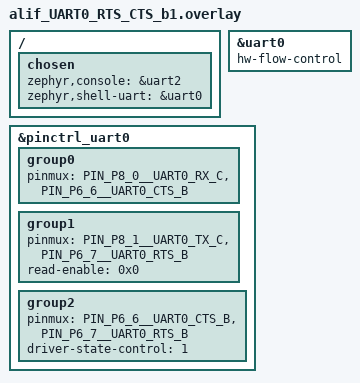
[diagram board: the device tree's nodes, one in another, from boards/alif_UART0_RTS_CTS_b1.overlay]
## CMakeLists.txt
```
cmake_minimum_required(VERSION 3.20.0)
find_package(Zephyr REQUIRED HINTS $ENV{ZEPHYR_BASE})

project(uart_tests)

target_sources(app PRIVATE
    src/main.c
)

# RTS/CTS lives in uart_internal_loopback.c (guarded by CONFIG_TEST_UART_RTSCTS).
# Compile that file when either the internal-loopback or the RTS/CTS suite
# is enabled so uart_RTSCTS_suite is not registered with zero tests.
if(CONFIG_TEST_INTERNAL_LB OR CONFIG_TEST_UART_RTSCTS)
  target_sources(app PRIVATE src/uart_internal_loopback.c)
endif()

target_sources_ifdef(CONFIG_TEST_EXTERNAL_LB app PRIVATE src/uart_external_loopback.c)

target_sources_ifdef(CONFIG_TEST_UART_DMA app PRIVATE src/uart_dma_tests.c)

target_sources_ifdef(CONFIG_TEST_STRESS app PRIVATE src/uart_stress.c)

target_sources_ifdef(CONFIG_TEST_PERFORMANCE app PRIVATE src/uart_perf.c)

target_sources_ifdef(CONFIG_TEST_UART_LINE_ERRORS app PRIVATE src/uart_line_errors.c)

if(CONFIG_TEST_INTERNAL_LB OR CONFIG_TEST_EXTERNAL_LB OR CONFIG_TEST_UART_FIFO)
  target_sources(app PRIVATE src/uart_fifo_depth.c)
endif()

target_sources_ifdef(CONFIG_TEST_UART_HOTPLUG app PRIVATE src/uart_hotplug.c)
```

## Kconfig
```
mainmenu "UART Test Suite Configuration"

source "Kconfig.zephyr"

config TEST_INTERNAL_LB
	bool "Enable UART internal loopback test suite"
	help
	  Build src/uart_internal_loopback.c and register
	  uart_internal_loopback.

config TEST_EXTERNAL_LB
	bool "Enable UART external loopback test suite"
	help
	  Build src/uart_external_loopback.c. Requires a physical TX-RX
	  connection between zephyr,devnode1 and zephyr,devnode2.

config TEST_UART_RTSCTS
	bool "Enable UART RTS/CTS flow control test suite"
	help
	  Builds src/uart_internal_loopback.c (same source as
	  TEST_INTERNAL_LB) so test_interrupt_internal_loopback_flowctrl_rts_cts
	  is compiled, and registers uart_RTSCTS_suite. Apply snippet
	  uart0-rts-cts (and boards/alif_uart.overlay) so hw-flow-control
	  is present on zephyr,devnode1.

config TEST_UART_DMA
	bool "Enable UART DMA async API test suite"
	help
	  Build src/uart_dma_tests.c. Also enable the DMA / async-API
	  options in dma.conf (EXTRA_CONF_FILE=dma.conf) and apply
	  snippet alif-uart-dma so zephyr,devnode1 is DMA-wired
	  (per-board overlay selected by the snippet).

config TEST_STRESS
	bool "Enable UART TX stress test suite"
	help
	  Build src/uart_stress.c and register uart_stress. Sends large
	  interrupt-driven TX bursts on zephyr,devnode1 (300 KiB and
	  1 250 000 bytes). Uses the overlay current-speed as baud rate.

config TEST_PERFORMANCE
	bool "Enable UART external-loopback performance test suite"
	help
	  Build src/uart_perf.c and register uart_performance. Requires
	  a physical TX-RX connection between zephyr,devnode1 and
	  zephyr,devnode2. Measures timed 1 KiB and 25 KiB transfers at
	  115200, 921600, 2500000, and 5000000 baud. Unsupported rates
	  are skipped at runtime.

config TEST_UART_LINE_ERRORS
	bool "Enable UART line-break and false-start-bit tests"
	select UART_LINE_CTRL
	select UART_NS16550_LINE_CTRL
	help
	  Build src/uart_line_errors.c. Needs TX-RX wire between
	  zephyr,devnode1 and zephyr,devnode2.

	  UART_LINE_CTRL enables the public uart_line_ctrl_set() API.
	  UART_NS16550_LINE_CTRL hooks the ns16550 driver (LCR break).
	  Without the second option uart_line_ctrl_set(BRK) returns
	  -ENOSYS and the suite skips.

config TEST_UART_FIFO
	  bool "Enable UART FIFO 32/33rd-byte boundary suite"
	  help
		Build src/uart_fifo_depth.c and register uart_fifo. TX 33rd
		byte is also built with TEST_INTERNAL_LB. RX 33rd byte needs
		a physical TX-RX wire (enable this flag or TEST_EXTERNAL_LB).

config TEST_UART_HOTPLUG
	bool "Enable UART hard-plug / unplug suite"
	help
		Build src/uart_hotplug.c and register uart_hotplug. Needs a
		TX-RX wire. Unmounts TX mid-transfer, checks RX stall latency
		and lost bytes, then remounts and recovers.
```

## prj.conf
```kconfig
CONFIG_SERIAL=y
CONFIG_UART_INTERRUPT_DRIVEN=y
CONFIG_ZTEST=y
CONFIG_EVENTS=y
CONFIG_LOG=y

CONFIG_MAIN_STACK_SIZE=2048
CONFIG_SYSTEM_WORKQUEUE_STACK_SIZE=2048

CONFIG_TEST_INTERNAL_LB=y
```

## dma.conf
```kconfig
# DMA-specific configuration for the UART DMA async-API test suite.
#
# Kept separate from prj.conf so that the DMA / async-API options do not
# affect the non-DMA UART test suites. Disables the interrupt-driven
# internal-loopback suite so it does not share zephyr,devnode1 with the
# DMA suite.

CONFIG_UART_ASYNC_API=y
CONFIG_DMA=y
CONFIG_DMA_PL330=y
CONFIG_TEST_UART_DMA=y
CONFIG_TEST_INTERNAL_LB=n
```

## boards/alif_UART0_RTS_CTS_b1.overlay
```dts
/* Copyright (C) 2025 Alif Semiconductor - All Rights Reserved.
 * Use, distribution and modification of this code is permitted under the
 * terms stated in the Alif Semiconductor Software License Agreement
 *
 * You should have received a copy of the Alif Semiconductor Software
 * License Agreement with this file. If not, please write to:
 * contact@alifsemi.com, or visit: https://alifsemi.com/license
 */

/* Enable H/W flow control(RTS-CTS) for UART0 */
/ {
	chosen {
		zephyr,console = &uart2;
		zephyr,shell-uart = &uart0;
	};
};

&uart0 {
	hw-flow-control;
	status = "okay";
};

&pinctrl_uart0 {
	group0 {
		pinmux = <PIN_P8_0__UART0_RX_C>,
			 <PIN_P6_6__UART0_CTS_B>;
	};
	group1 {
		pinmux = <PIN_P8_1__UART0_TX_C>,
			 <PIN_P6_7__UART0_RTS_B>;
		read-enable = <0x0>;
	};
	group2 {
		pinmux = <PIN_P6_6__UART0_CTS_B>,
			 <PIN_P6_7__UART0_RTS_B>;
		driver-state-control = <1>;
	};
};
```

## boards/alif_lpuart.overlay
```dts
/ {
	chosen {
		zephyr,devnode1 = &lpuart;
		zephyr,devnode2 = &uart1;
	};
};

&lpuart {
	status = "okay";
};

&uart1 {
	status = "okay";
};
```

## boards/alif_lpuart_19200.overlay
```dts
/ {
	chosen {
		zephyr,devnode1 = &lpuart;
		zephyr,devnode2 = &uart5;
	};
};

&lpuart {
	current-speed = <19200>;
	status = "okay";
};

&uart5 {
	current-speed = <19200>;
	status = "okay";
};
```

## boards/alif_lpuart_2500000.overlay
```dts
/ {
	chosen {
		zephyr,devnode1 = &lpuart;
		zephyr,devnode2 = &uart5;
	};
};

&lpuart {
	current-speed = <2500000>;
	status = "okay";
};

&uart5 {
	current-speed = <2500000>;
	status = "okay";
};
```

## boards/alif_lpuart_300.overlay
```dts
/ {
	chosen {
		zephyr,devnode1 = &lpuart;
		zephyr,devnode2 = &uart5;
	};
};

&lpuart {
	current-speed = <300>;
	status = "okay";
};

&uart5 {
	current-speed = <300>;
	status = "okay";
};
```

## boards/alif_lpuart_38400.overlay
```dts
/ {
	chosen {
		zephyr,devnode1 = &lpuart;
		zephyr,devnode2 = &uart5;
	};
};

&lpuart {
	current-speed = <38400>;
	status = "okay";
};

&uart5 {
	current-speed = <38400>;
	status = "okay";
};
```

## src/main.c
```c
/* Copyright (C) Alif Semiconductor - All Rights Reserved.
 * Use, distribution and modification of this code is permitted under the
 * terms stated in the Alif Semiconductor Software License Agreement
 *
 * You should have received a copy of the Alif Semiconductor Software
 * License Agreement with this file. If not, please write to:
 * contact@alifsemi.com, or visit: https://alifsemi.com/license
 */

/**
 * @file
 * @brief UART test shared state, utility helpers, and test-suite registration.
 *
 * This file owns the global UART configuration structs and ISR-shared
 * variables consumed by the loopback, stress, and performance modules.
 * It also provides small helper functions
 * (baud-rate look-up, config-result checking, IRQ-callback validation)
 * and the ZTEST_SUITE() declarations gated by Kconfig flags.
 */

#include "test_uart.h"

/*
 * ---------------------------------------------------------------------------
 *  UART configuration structs — one per logical role.
 *  All default to 115200 / 8N1 / no flow-control.
 * ---------------------------------------------------------------------------
 */
struct uart_config uart_cfg = {
	.baudrate  = 115200,
	.parity    = UART_CFG_PARITY_NONE,
	.stop_bits = UART_CFG_STOP_BITS_1,
	.data_bits = UART_CFG_DATA_BITS_8,
	.flow_ctrl = UART_CFG_FLOW_CTRL_NONE,
};

struct uart_config uart_cfg_rx = {
	.baudrate  = 115200,
	.parity    = UART_CFG_PARITY_NONE,
	.stop_bits = UART_CFG_STOP_BITS_1,
	.data_bits = UART_CFG_DATA_BITS_8,
	.flow_ctrl = UART_CFG_FLOW_CTRL_NONE,
};

struct uart_config uart_cfg_tx = {
	.baudrate  = 115200,
	.parity    = UART_CFG_PARITY_NONE,
	.stop_bits = UART_CFG_STOP_BITS_1,
	.data_bits = UART_CFG_DATA_BITS_8,
	.flow_ctrl = UART_CFG_FLOW_CTRL_NONE,
};

/*
 * ---------------------------------------------------------------------------
 *  ISR-shared state: internal loopback ("auto") path
 * ---------------------------------------------------------------------------
 */
volatile bool data_transmitted_auto;
volatile bool data_received_auto;
volatile int tx_data_idx1;
volatile int rec_count_auto;
volatile int char_sent1;
uint8_t rx_verify_buf_auto[DATASIZE];

/*
 * ---------------------------------------------------------------------------
 *  ISR-shared state: external loopback path
 * ---------------------------------------------------------------------------
 */
volatile bool data_transmitted;
volatile bool data_received;
volatile int tx_data_idx;
volatile int char_sent;
volatile int rec_bytes;

/*
 * ---------------------------------------------------------------------------
 *  Utility helpers
 * ---------------------------------------------------------------------------
 */

/**
 * @brief Set the baud rate of a UART device at runtime.
 *
 * Reads the current configuration via uart_config_get(), updates only
 * the baud-rate field, then applies it with uart_configure().  This
 * lets a single compiled binary test every supported rate without
 * per-baud overlay recompilation.
 *
 * @param uart_dev       UART device to reconfigure.
 * @param test_baudrate  Desired baud rate in bps.
 * @return 0 on success, negative errno on failure.
 */
int set_baudrate(const struct device *uart_dev, uint32_t test_baudrate)
{
	struct uart_config current_cfg;
	int err;

	err = uart_config_get(uart_dev, &current_cfg);
	if (err != 0) {
		TC_PRINT("uart_config_get failed (ret=%d)\n", err);
		return err;
	}

	current_cfg.baudrate = test_baudrate;
	err = uart_configure(uart_dev, &current_cfg);
	if (err != 0) {
		TC_PRINT("uart_configure failed for baudrate %u (ret=%d)\n",
			 test_baudrate, err);
	}

	return err;
}

int check_baud(int num)
{
	switch (num) {
	case UART_BAUD_300:
		return 300;
	case UART_BAUD_9600:
		return 9600;
	case UART_BAUD_19200:
		return 19200;
	case UART_BAUD_38400:
		return 38400;
	case UART_BAUD_57600:
		return 57600;
	case UART_BAUD_115200:
		return 115200;
	case UART_BAUD_921600:
		return 921600;
	case UART_BAUD_2500000:
		return 2500000;
	default:
		TC_PRINT("INVALID BAUDRATE\t");
		return TC_SKIP;
	}
}

int check_stop_bits(int num)
{
	switch (num) {
	case UART_CFG_STOP_BITS_0_5:
		TC_PRINT("\nUART_CFG_STOP_BITS_0_5\n");
		return UART_CFG_STOP_BITS_0_5;
	case UART_CFG_STOP_BITS_1:
		TC_PRINT("\nUART_CFG_STOP_BITS_1\n");
		return UART_CFG_STOP_BITS_1;
	case UART_CFG_STOP_BITS_1_5:
		TC_PRINT("\nUART_CFG_STOP_BITS_1_5\n");
		return UART_CFG_STOP_BITS_1_5;
	case UART_CFG_STOP_BITS_2:
		TC_PRINT("\nUART_CFG_STOP_BITS_2\n");
		return UART_CFG_STOP_BITS_2;
	default:
		TC_PRINT("\nINVALID STOP BITS\n");
		return TC_SKIP;
	}
}

/**
 * @brief Map a parity index to its Zephyr UART_CFG_PARITY_* constant.
 *
 * @param num  Parity selector (0 = none … 4 = space).
 * @return The corresponding UART_CFG_PARITY_* value, or TC_SKIP.
 */
int check_parity_bits(int num)
{
	switch (num) {
	case UART_CFG_PARITY_NONE:
		TC_PRINT("\nUART_CFG_PARITY_NONE\n");
		return UART_CFG_PARITY_NONE;
	case UART_CFG_PARITY_ODD:
		TC_PRINT("\nUART_CFG_PARITY_ODD\n");
		return UART_CFG_PARITY_ODD;
	case UART_CFG_PARITY_EVEN:
		TC_PRINT("\nUART_CFG_PARITY_EVEN\n");
		return UART_CFG_PARITY_EVEN;
	case UART_CFG_PARITY_MARK:
		TC_PRINT("\nUART_CFG_PARITY_MARK\n");
		return UART_CFG_PARITY_MARK;
	case UART_CFG_PARITY_SPACE:
		TC_PRINT("\nUART_CFG_PARITY_SPACE\n");
		return UART_CFG_PARITY_SPACE;
	default:
		TC_PRINT("\nINVALID PARITY\n");
		return TC_SKIP;
	}
}

/**
 * @brief Non-fatal check of uart_configure() return value.
 *
 * Prints a diagnostic and returns -1 on any error so that the caller
 * can skip the current baud-rate / config iteration without aborting
 * the entire test.
 *
 * @param ret  Return value from uart_configure().
 * @return 0 on success, -1 on failure.
 */
int check_configure_result_loopback(int ret)
{
	switch (ret) {
	case -ENOSYS:
		TC_PRINT("Configuration not supported by device or driver\n");
		return -1;
	case -ENOTSUP:
		TC_PRINT("API is not enabled\n");
		return -1;
	default:
		if (ret < 0) {
			TC_PRINT("Negative errno %d\n", ret);
			return -1;
		} else if (ret != 0) {
			TC_PRINT("Configuration failed\n");
			return -1;
		}
		TC_PRINT("Configuration passed\n");
		return 0;
	}
}

/**
 * @brief Fatal check of uart_configure() return value.
 *
 * Calls zassert_equal(); the test is aborted if @p ret != 0.
 *
 * @param ret  Return value from uart_configure().
 * @return 0 (only reached on success).
 */
int check_configure_result(int ret)
{
	zassert_equal(ret, 0, "UART configuration failed (ret=%d)", ret);
	return 0;
}

int uart_irq_cb(int ret)
{
	switch (ret) {
	case 0:
		return 0;
	case -ENOSYS:
		TC_PRINT("Function is not supported\n");
		return -1;
	case -ENOTSUP:
		TC_PRINT("API is not enabled\n");
		return -1;
	default:
		if (ret < 0) {
			TC_PRINT("Negative errno %d from uart_irq_callback_user_data_set\n", ret);
			return -1;
		} else if (ret != 0) {
			TC_PRINT("Unexpected non-zero return value %d from "
			 "uart_irq_callback_user_data_set\n", ret);
			return -1;
		}
	}

	return 0;
}

/*
 * ---------------------------------------------------------------------------
 *  Test-suite registration (gated by Kconfig)
 * ---------------------------------------------------------------------------
 */

#if CONFIG_TEST_EXTERNAL_LB
/** External-loopback suite — requires a physical TX→RX wire between devnode1
 *  and devnode2.  Enabled with CONFIG_TEST_EXTERNAL_LB=y.
 */
ZTEST_SUITE(uart_external_loopback, NULL, NULL, NULL, NULL, NULL);
#endif

#if CONFIG_TEST_INTERNAL_LB
/** Internal-loopback suite — uses the UART's built-in loopback mode on
 *  devnode1.  Enabled with CONFIG_TEST_INTERNAL_LB=y.
 */
ZTEST_SUITE(uart_internal_loopback, NULL, NULL, NULL, NULL, NULL);
#endif

#if CONFIG_TEST_UART_RTSCTS
/** RTS/CTS flow control suite — tests hardware flow control on
 *  devnode1.  Enabled with CONFIG_TEST_UART_RTSCTS=y.
 */
ZTEST_SUITE(uart_RTSCTS_suite, NULL, NULL, NULL, NULL, NULL);
#endif

#if CONFIG_TEST_STRESS
/** TX stress suite — large interrupt-driven bursts on devnode1.
 *  Enabled with CONFIG_TEST_STRESS=y.
 */
ZTEST_SUITE(uart_stress, NULL, NULL, NULL, NULL, NULL);
#endif

#if CONFIG_TEST_PERFORMANCE
/** External-loopback performance suite — timed transfers between
 *  devnode1 and devnode2.  Enabled with CONFIG_TEST_PERFORMANCE=y.
 */
ZTEST_SUITE(uart_performance, NULL, NULL, NULL, NULL, NULL);
#endif
#if CONFIG_TEST_UART_LINE_ERRORS
ZTEST_SUITE(uart_line_errors, NULL, NULL, NULL, NULL, NULL);
#endif

#if CONFIG_TEST_INTERNAL_LB || CONFIG_TEST_EXTERNAL_LB || CONFIG_TEST_UART_FIFO
/** FIFO depth / 33rd-byte boundary (TX always; RX needs a wire). */
ZTEST_SUITE(uart_fifo, NULL, NULL, NULL, NULL, NULL);
#endif

/*
 * uart_hotplug is registered in uart_hotplug.c so its after-hook can
 * resume a suspended TX UART even when an assertion fails.
 * uart_dma is registered in uart_dma_tests.c for the same reason:
 * its before/after hooks own DMA buffer setup and release.
 */
```

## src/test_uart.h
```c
/* Copyright (C) Alif Semiconductor - All Rights Reserved.
 * Use, distribution and modification of this code is permitted under the
 * terms stated in the Alif Semiconductor Software License Agreement
 *
 * You should have received a copy of the Alif Semiconductor Software
 * License Agreement with this file. If not, please write to:
 * contact@alifsemi.com, or visit: https://alifsemi.com/license
 */
/**
 * @file
 * @brief UART test cases header file
 *
 * Common declarations for UART test suite covering internal/external
 * loopback, RTS/CTS, stress, and performance tests on Alif platforms.
 */

#ifndef TEST_UART_H_
#define TEST_UART_H_

#include <zephyr/drivers/uart.h>
#include <zephyr/ztest.h>
#include <zephyr/sys/util.h>

#if !DT_HAS_CHOSEN(zephyr_devnode1)
#error "Need DT chosen zephyr,devnode1 (alif_uart or alif_lpuart overlay)"
#endif

#if !DT_HAS_CHOSEN(zephyr_devnode2) && \
	(CONFIG_TEST_EXTERNAL_LB || CONFIG_TEST_PERFORMANCE || \
	 CONFIG_TEST_UART_LINE_ERRORS || CONFIG_TEST_UART_HOTPLUG)
#error "Need DT chosen zephyr,devnode2 (apply boards/alif_uart.overlay)"
#endif

/** Maximum receive-buffer size shared across test modules. */
#define DATASIZE        128

/** Hardware FIFO depth (bytes) for a single uart_fifo_fill / uart_fifo_read. */
#define FIFO_DEPTH      32

/** k_event bit signalling TX completion inside an ISR callback. */
#define TX_DONE_EVENT   BIT(0)

/** k_event bit signalling RX completion inside an ISR callback. */
#define RX_DONE_EVENT   BIT(1)

/** Floor value (ms) returned by uart_test_timeout_ms() for fast baud rates. */
#define UART_TEST_TIMEOUT_MS  3000

/**
 * @brief Compute a safe per-transfer timeout in milliseconds.
 *
 * Uses 8N1 framing (10 bits per byte) to estimate the raw transfer time,
 * then applies a 3x multiplier plus a 2 s margin.  Never returns less than
 * @ref UART_TEST_TIMEOUT_MS so that high-baud-rate transfers still get a
 * reasonable deadline.
 *
 * @param baudrate  Configured baud rate (bps).
 * @param size      Number of bytes to transfer.
 * @return Timeout in milliseconds.
 */
static inline int64_t uart_test_timeout_ms(uint32_t baudrate, int size)
{
	int64_t transfer_ms = ((int64_t)size * 10 * 1000) / baudrate;
	int64_t timeout = transfer_ms * 3 + 2000; /* 3x transfer time + 2s margin */

	return (timeout > UART_TEST_TIMEOUT_MS) ? timeout : UART_TEST_TIMEOUT_MS;
}

/*
 * Context structure passed as user_data to ISR callbacks.
 * Avoids calling strlen() in ISR context and supports binary data.
 */
struct uart_cb_ctx {
	const uint8_t *buf;  /* TX data buffer */
	int size;            /* TX data length (no NUL dependency) */
};

typedef enum {
	UART_BAUD_300,
	UART_BAUD_9600,
	UART_BAUD_19200,
	UART_BAUD_38400,
	UART_BAUD_57600,
	UART_BAUD_115200,
	UART_BAUD_921600,
	UART_BAUD_2500000,
} uart_config_baudrates;

/* Automation (internal loopback) state */
extern volatile bool data_transmitted_auto;
extern volatile bool data_received_auto;
extern volatile int tx_data_idx1;
extern volatile int rec_count_auto;
extern volatile int char_sent1;
extern uint8_t rx_verify_buf_auto[];

/* Manual (external loopback / stress) state */
extern volatile bool data_transmitted;
extern volatile bool data_received;
extern volatile int tx_data_idx;
extern volatile int char_sent;
extern volatile int rec_bytes;

extern struct uart_config uart_cfg;
extern struct uart_config uart_cfg_rx;
extern struct uart_config uart_cfg_tx;

/* Utility functions (main.c) */
extern int set_baudrate(const struct device *uart_dev, uint32_t test_baudrate);
extern int check_baud(int num);
extern int check_stop_bits(int num);
extern int check_parity_bits(int num);
extern int check_configure_result(int ret);
extern int check_configure_result_loopback(int ret);
extern int uart_irq_cb(int ret);

/* Helper macro to get current-speed from devicetree */
#define UART_GET_BAUDRATE(node) DT_PROP_OR(node, current_speed, 115200)

static inline uint32_t get_uart_baudrate_from_dt(void)
{
	return UART_GET_BAUDRATE(DT_CHOSEN(zephyr_devnode1));
}

#endif /* TEST_UART_H_ */
```

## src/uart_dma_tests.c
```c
/* Copyright (C) Alif Semiconductor - All Rights Reserved.
 * Use, distribution and modification of this code is permitted under the
 * terms stated in the Alif Semiconductor Software License Agreement
 *
 * You should have received a copy of the Alif Semiconductor Software
 * License Agreement with this file. If not, please write to:
 * contact@alifsemi.com, or visit: https://alifsemi.com/license
 */

#include <string.h>
#include "test_uart.h"

#if CONFIG_TEST_UART_DMA

#define RX_BUF_SIZE        64
#define TX_BUF_SIZE        64
#define TX_ABORT_BUF_SIZE  128

/*
 * RX may be fragmented across multiple UART_RX_RDY events. Each fragment
 * is pushed onto a message queue so that events arriving before the test
 * thread consumes them are preserved. A single semaphore would coalesce
 * (max-count) the events and the shared globals would be overwritten,
 * dropping earlier fragments.
 */
#define RX_MSGQ_DEPTH      16

struct rx_chunk {
	uint8_t *buf;
	size_t   offset;
	size_t   len;
};

static uint8_t rx_dma_buf_a[RX_BUF_SIZE];
static uint8_t rx_dma_buf_b[RX_BUF_SIZE];
static uint8_t tx_dma_buf[TX_BUF_SIZE];
static uint8_t tx_abort_buf[TX_ABORT_BUF_SIZE];

K_MSGQ_DEFINE(rx_msgq, sizeof(struct rx_chunk), RX_MSGQ_DEPTH, 4);

static struct k_sem tx_done_sem;
static struct k_sem rx_disabled_sem;
static struct k_sem buf_req_sem;
static struct k_sem buf_released_sem;

static volatile int last_tx_evt;

/* DMA-capable UART device under test (devnode1), resolved in the before hook. */
static const struct device *dma_uart_dev;

static void uart_dma_cb(const struct device *dev, struct uart_event *evt,
			void *user_data)
{
	ARG_UNUSED(dev);
	ARG_UNUSED(user_data);

	switch (evt->type) {
	case UART_RX_RDY: {
		struct rx_chunk chunk = {
			.buf    = evt->data.rx.buf,
			.offset = evt->data.rx.offset,
			.len    = evt->data.rx.len,
		};

		if (k_msgq_put(&rx_msgq, &chunk, K_NO_WAIT) != 0) {
			TC_PRINT("RX msgq overflow: dropping UART_RX_RDY fragment\n");
		}
		break;
	}
	case UART_TX_DONE:
		last_tx_evt = evt->type;
		TC_PRINT("UART_TX_DONE\n");
		k_sem_give(&tx_done_sem);
		break;
	case UART_TX_ABORTED:
		last_tx_evt = evt->type;
		TC_PRINT("UART_TX_ABORTED\n");
		k_sem_give(&tx_done_sem);
		break;
	case UART_RX_BUF_REQUEST:
		TC_PRINT("UART_RX_BUF_REQUEST\n");
		k_sem_give(&buf_req_sem);
		break;
	case UART_RX_BUF_RELEASED:
		TC_PRINT("UART_RX_BUF_RELEASED\n");
		k_sem_give(&buf_released_sem);
		break;
	case UART_RX_DISABLED:
		TC_PRINT("UART_RX_DISABLED\n");
		k_sem_give(&rx_disabled_sem);
		break;
	default:
		break;
	}
}

static int dma_uart_send(const struct device *dev, const uint8_t *data,
			 size_t len)
{
	int ret;

	ret = uart_tx(dev, data, len, SYS_FOREVER_US);
	if (ret < 0) {
		return ret;
	}

	ret = k_sem_take(&tx_done_sem, K_SECONDS(5));
	return ret;
}

/*
 * Per-test setup, invoked by the ztest framework before every test in
 * the uart_dma suite. Validates device readiness, resets all
 * synchronization primitives and buffers, and (re)installs the async
 * callback so each test starts from a clean, known state.
 */
static void uart_dma_before(void *fixture)
{
	ARG_UNUSED(fixture);
	int ret;

	dma_uart_dev = DEVICE_DT_GET(DT_CHOSEN(zephyr_devnode1));
	zassert_true(device_is_ready(dma_uart_dev),
		     "%s UART device not ready", dma_uart_dev->name);
	TC_PRINT("%s UART device is ready\n", dma_uart_dev->name);

	k_sem_init(&tx_done_sem, 0, 1);
	k_sem_init(&rx_disabled_sem, 0, 1);
	k_sem_init(&buf_req_sem, 0, 1);
	k_sem_init(&buf_released_sem, 0, 1);
	k_msgq_purge(&rx_msgq);

	last_tx_evt = -1;

	memset(rx_dma_buf_a, 0, RX_BUF_SIZE);
	memset(rx_dma_buf_b, 0, RX_BUF_SIZE);
	memset(tx_dma_buf, 0, TX_BUF_SIZE);

	ret = uart_callback_set(dma_uart_dev, uart_dma_cb, NULL);
	zassert_equal(ret, 0, "uart_callback_set failed (ret=%d)", ret);
}

/*
 * Per-test teardown: abort any in-flight TX and disable RX so the DMA
 * buffers are released and re-acquired cleanly between test cases,
 * regardless of whether the test passed or failed.
 */
static void uart_dma_after(void *fixture)
{
	ARG_UNUSED(fixture);

	if (dma_uart_dev == NULL) {
		return;
	}

	(void)uart_tx_abort(dma_uart_dev);
	if (uart_rx_disable(dma_uart_dev) == 0) {
		(void)k_sem_take(&rx_disabled_sem, K_SECONDS(1));
	}
}

/**
 * @brief Basic DMA TX/RX loopback test.
 *
 * Transmits a short string via DMA and verifies the identical
 * payload is received back via DMA RX.
 */
ZTEST(uart_dma, test_dma_basic_tx_rx)
{
	int ret;
	uint8_t tx_payload[] = "DMA loopback test!";
	size_t tx_len = strlen((char *)tx_payload);

	ret = uart_rx_enable(dma_uart_dev, rx_dma_buf_a, RX_BUF_SIZE, 1000);
	zassert_equal(ret, 0, "uart_rx_enable failed (ret=%d)", ret);

	memcpy(tx_dma_buf, tx_payload, tx_len);
	ret = dma_uart_send(dma_uart_dev, tx_dma_buf, tx_len);
	zassert_equal(ret, 0, "dma_uart_send failed (ret=%d)", ret);

	/*
	 * RX may be fragmented across multiple UART_RX_RDY events, so
	 * accumulate and verify chunks from the queue until the full
	 * payload arrives.
	 */
	size_t received = 0;

	while (received < tx_len) {
		struct rx_chunk chunk;

		ret = k_msgq_get(&rx_msgq, &chunk, K_MSEC(5000));
		zassert_equal(ret, 0, "RX timeout waiting for data");
		zassert_not_null(chunk.buf, "RX buffer is NULL");
		zassert_true(chunk.offset + chunk.len <= RX_BUF_SIZE,
			     "RX chunk out of bounds (offset=%zu len=%zu)",
			     chunk.offset, chunk.len);
		zassert_true(received + chunk.len <= tx_len,
			     "RX longer than expected (received=%zu chunk=%zu expected=%zu)",
			     received, chunk.len, tx_len);
		zassert_equal(memcmp(chunk.buf + chunk.offset,
				     tx_payload + received, chunk.len), 0,
			      "RX data mismatch");
		received += chunk.len;
	}

	zassert_equal(received, tx_len,
		      "RX length mismatch: expected %zu, got %zu",
		      tx_len, received);

	ret = uart_rx_disable(dma_uart_dev);
	zassert_equal(ret, 0, "uart_rx_disable failed (ret=%d)", ret);

	ret = k_sem_take(&rx_disabled_sem, K_MSEC(1000));
	zassert_equal(ret, 0, "RX disabled event timeout");

	TC_PRINT("DMA basic TX/RX test PASSED\n");
}

/**
 * @brief DMA RX double-buffer request/release test.
 *
 * Enables double-buffered DMA RX, fills both buffers, and verifies
 * that UART_RX_BUF_REQUEST and UART_RX_BUF_RELEASED events fire.
 */
ZTEST(uart_dma, test_dma_rx_buf_request_release)
{
	int ret;
	uint8_t tx_payload[RX_BUF_SIZE * 2];
	size_t tx_len = sizeof(tx_payload);
	struct rx_chunk chunk;

	for (size_t i = 0; i < tx_len; i++) {
		tx_payload[i] = (uint8_t)i;
	}

	ret = uart_rx_enable(dma_uart_dev, rx_dma_buf_a, RX_BUF_SIZE, 1000);
	zassert_equal(ret, 0, "uart_rx_enable failed (ret=%d)", ret);

	/* Start TX without waiting so we can respond to RX buffer requests. */
	ret = uart_tx(dma_uart_dev, tx_payload, tx_len, SYS_FOREVER_US);
	zassert_equal(ret, 0, "uart_tx failed (ret=%d)", ret);

	ret = k_sem_take(&buf_req_sem, K_MSEC(5000));
	zassert_equal(ret, 0, "UART_RX_BUF_REQUEST event timeout");

	ret = uart_rx_buf_rsp(dma_uart_dev, rx_dma_buf_b, RX_BUF_SIZE);
	zassert_equal(ret, 0, "uart_rx_buf_rsp failed (ret=%d)", ret);

	ret = k_sem_take(&tx_done_sem, K_MSEC(5000));
	zassert_equal(ret, 0, "TX timeout waiting for completion");

	/*
	 * RX_RDY can fire for each buffer. Accumulate every chunk and
	 * check it against the payload so a bad switch to the second
	 * buffer cannot pass on the first chunk alone.
	 */
	size_t received = 0;

	while (received < tx_len) {
		ret = k_msgq_get(&rx_msgq, &chunk, K_MSEC(5000));
		zassert_equal(ret, 0, "RX timeout waiting for data");
		zassert_not_null(chunk.buf, "RX buffer is NULL");
		zassert_true(chunk.offset + chunk.len <= RX_BUF_SIZE,
			     "RX chunk out of bounds (offset=%zu len=%zu)",
			     chunk.offset, chunk.len);
		zassert_true(received + chunk.len <= tx_len,
			     "RX longer than expected (received=%zu chunk=%zu expected=%zu)",
			     received, chunk.len, tx_len);
		zassert_equal(memcmp(chunk.buf + chunk.offset,
				     tx_payload + received, chunk.len), 0,
			      "RX data mismatch at offset %zu", received);
		received += chunk.len;
	}

	zassert_equal(received, tx_len,
		      "RX length mismatch: expected %zu, got %zu",
		      tx_len, received);

	ret = k_sem_take(&buf_released_sem, K_MSEC(1000));
	zassert_equal(ret, 0, "UART_RX_BUF_RELEASED event timeout");

	ret = uart_rx_disable(dma_uart_dev);
	zassert_equal(ret, 0, "uart_rx_disable failed (ret=%d)", ret);

	ret = k_sem_take(&rx_disabled_sem, K_MSEC(1000));
	zassert_equal(ret, 0, "RX disabled event timeout");

	TC_PRINT("DMA RX buffer request/release test PASSED\n");
}

/**
 * @brief DMA TX abort test.
 *
 * Follows tests/drivers/uart/uart_async_api: enable RX, complete a short
 * TX so the channel is known-good, start a longer TX and abort it at
 * once. Do not sleep first - after the UART FIFO fills, PL330 sits in
 * DMAWFP (wait-for-peripheral). DMAKILL from that state is taken with
 * IRQs locked inside dma_pl330_transfer_stop() and can freeze the
 * console / never return.
 */
ZTEST(uart_dma, test_dma_tx_abort)
{
	int ret;

	for (size_t i = 0; i < sizeof(tx_abort_buf); i++) {
		tx_abort_buf[i] = (uint8_t)i;
	}

	ret = uart_rx_enable(dma_uart_dev, rx_dma_buf_a, RX_BUF_SIZE,
			     SYS_FOREVER_US);
	zassert_equal(ret, 0, "uart_rx_enable failed (ret=%d)", ret);

	/* Prime: a short transfer that is allowed to finish. */
	ret = uart_tx(dma_uart_dev, tx_abort_buf, 8, SYS_FOREVER_US);
	zassert_equal(ret, 0, "prime uart_tx failed (ret=%d)", ret);
	ret = k_sem_take(&tx_done_sem, K_MSEC(1000));
	zassert_equal(ret, 0, "prime TX_DONE timeout");
	zassert_equal(last_tx_evt, UART_TX_DONE,
		      "prime TX expected TX_DONE, got %d", last_tx_evt);

	last_tx_evt = -1;
	k_sem_reset(&tx_done_sem);

	ret = uart_tx(dma_uart_dev, tx_abort_buf, sizeof(tx_abort_buf),
		      SYS_FOREVER_US);
	zassert_equal(ret, 0, "uart_tx failed (ret=%d)", ret);

	ret = uart_tx_abort(dma_uart_dev);
	zassert_equal(ret, 0, "uart_tx_abort failed (ret=%d)", ret);

	ret = k_sem_take(&tx_done_sem, K_MSEC(1000));
	zassert_equal(ret, 0, "TX abort event timeout");
	zassert_equal(last_tx_evt, UART_TX_ABORTED,
		      "Expected UART_TX_ABORTED, got %d", last_tx_evt);

	ret = uart_rx_disable(dma_uart_dev);
	zassert_equal(ret, 0, "uart_rx_disable failed (ret=%d)", ret);
	ret = k_sem_take(&rx_disabled_sem, K_MSEC(1000));
	zassert_equal(ret, 0, "RX disabled event timeout");

	TC_PRINT("DMA TX abort test PASSED\n");
}

/**
 * @brief DMA RX timeout test.
 *
 * Sends a payload smaller than the RX buffer over the loopback and
 * verifies the partial data is reported via UART_RX_RDY because of the
 * RX idle timeout. Without the timeout, a buffer that never fills would
 * not produce an RX_RDY event. Per the Zephyr async API, an RX timeout
 * delivers UART_RX_RDY (not UART_RX_DISABLED), and this driver only arms
 * the idle-timeout timer once data arrives (via the character-timeout
 * interrupt), so a small transfer is required to exercise the feature.
 */
ZTEST(uart_dma, test_dma_rx_timeout)
{
	int ret;
	uint8_t tx_payload[] = "RXto";
	size_t tx_len = strlen((char *)tx_payload);
	struct rx_chunk chunk;

	/* Buffer is intentionally larger than the payload so the transfer
	 * completes only via the RX idle timeout, not a full-buffer event.
	 */
	ret = uart_rx_enable(dma_uart_dev, rx_dma_buf_a, RX_BUF_SIZE, 100);
	zassert_equal(ret, 0, "uart_rx_enable failed (ret=%d)", ret);

	memcpy(tx_dma_buf, tx_payload, tx_len);
	ret = dma_uart_send(dma_uart_dev, tx_dma_buf, tx_len);
	zassert_equal(ret, 0, "dma_uart_send failed (ret=%d)", ret);

	/* RX_RDY must arrive via the idle timeout for the partial payload. */
	ret = k_msgq_get(&rx_msgq, &chunk, K_MSEC(5000));
	zassert_equal(ret, 0, "RX timeout did not deliver data");
	zassert_not_null(chunk.buf, "RX buffer is NULL");
	zassert_true(chunk.len > 0 && chunk.len <= tx_len,
		     "Unexpected RX chunk length %zu", chunk.len);
	zassert_equal(memcmp(chunk.buf + chunk.offset, tx_payload, chunk.len),
		      0, "RX data mismatch");

	ret = uart_rx_disable(dma_uart_dev);
	zassert_equal(ret, 0, "uart_rx_disable failed (ret=%d)", ret);

	ret = k_sem_take(&rx_disabled_sem, K_MSEC(1000));
	zassert_equal(ret, 0, "RX disabled event timeout");

	TC_PRINT("DMA RX timeout test PASSED\n");
}

/*
 * DMA async-API suite. The before hook validates device readiness and
 * resets state before every test; the after hook releases the DMA
 * buffers (abort TX, disable RX) so buffers are cleanly re-acquired.
 */
ZTEST_SUITE(uart_dma, NULL, NULL, uart_dma_before, uart_dma_after, NULL);

#endif /* CONFIG_TEST_UART_DMA */
```

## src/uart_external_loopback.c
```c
/* Copyright (C) Alif Semiconductor - All Rights Reserved.
 * Use, distribution and modification of this code is permitted under the
 * terms stated in the Alif Semiconductor Software License Agreement
 *
 * You should have received a copy of the Alif Semiconductor Software
 * License Agreement with this file. If not, please write to:
 * contact@alifsemi.com, or visit: https://alifsemi.com/license
 */

#include <string.h>
#include "test_uart.h"

static struct k_event uart_events;
static unsigned char global_rx_buffer[DATASIZE];

static void print_buffer_hex_ascii(const char *label, const unsigned char *buf,
				   int len)
{
	TC_PRINT("%s (%d bytes)\n", label, len);
	TC_PRINT("HEX: ");
	for (int i = 0; i < len; i++) {
		TC_PRINT("%02X ", buf[i]);
	}
	TC_PRINT("\nASCII: ");
	for (int i = 0; i < len; i++) {
		unsigned char c = buf[i];

		TC_PRINT("%c", (c >= 32 && c <= 126) ? c : '.');
	}
	TC_PRINT("\n");
}

static void print_buffer_hex_only(const char *label, const unsigned char *buf,
				  int len)
{
	TC_PRINT("%s (%d bytes)\n", label, len);
	for (int i = 0; i < len; i++) {
		TC_PRINT("%02X ", buf[i]);
	}
	TC_PRINT("\n");
}

/*
 * TX-only callback for external loopback.
 * Uses struct uart_cb_ctx to know the buffer size without strlen().
 */
static void uart_external_loopback_tx_cb(const struct device *dev,
					 void *user_data)
{
	struct uart_cb_ctx *ctx = (struct uart_cb_ctx *)user_data;
	int ret;

	ret = uart_irq_update(dev);
	if (ret <= 0) {
		return;
	}

	if (uart_irq_tx_ready(dev)) {
		int remaining = ctx->size - tx_data_idx;

		if (remaining > 0) {
			ret = uart_fifo_fill(dev,
					     &ctx->buf[tx_data_idx],
					     remaining);
			if (ret > 0) {
				tx_data_idx += ret;
			}
		}

		if (tx_data_idx >= ctx->size) {
			data_transmitted = true;
			char_sent = ctx->size;
			k_event_set(&uart_events, TX_DONE_EVENT);
			uart_irq_tx_disable(dev);
		}
	}
}

/*
 * RX-only callback for external loopback.
 * Reads into global_rx_buffer; signals RX_DONE when expected bytes arrive.
 */
static void uart_external_loopback_rx_cb(const struct device *dev,
					 void *user_data)
{
	struct uart_cb_ctx *ctx = (struct uart_cb_ctx *)user_data;
	int ret;

	ret = uart_irq_update(dev);
	if (ret <= 0) {
		return;
	}

	if (uart_irq_rx_ready(dev)) {
		int read_limit = (ctx->size > DATASIZE)
				 ? DATASIZE : ctx->size;

		while (rec_bytes < read_limit && uart_irq_rx_ready(dev)) {
			int rd = uart_fifo_read(dev,
					       &global_rx_buffer[rec_bytes],
					       read_limit - rec_bytes);
			if (rd > 0) {
				rec_bytes += rd;
			} else {
				break;
			}
		}

		if (rec_bytes >= read_limit) {
			data_received = true;
			uart_irq_rx_disable(dev);
			k_event_set(&uart_events, RX_DONE_EVENT);
		}
	}
}

static int test_external_loopback_interrupt(const uint8_t *tx_buf, int size,
					  const char *str)
{
	int ret;
	struct uart_cb_ctx tx_ctx = { .buf = tx_buf, .size = size };
	struct uart_cb_ctx rx_ctx = { .buf = NULL, .size = size };

	zassert_true(size > 0, "TX buffer size must be > 0");
	zassert_true(size <= DATASIZE, "TX buffer exceeds DATASIZE");

	const struct device *tx_dev = DEVICE_DT_GET(DT_CHOSEN(zephyr_devnode1));
	const struct device *rx_dev = DEVICE_DT_GET(DT_CHOSEN(zephyr_devnode2));

	zassert_true(device_is_ready(tx_dev), "TX UART device not ready");
	zassert_true(device_is_ready(rx_dev), "RX UART device not ready");

	char_sent = 0;
	tx_data_idx = 0;
	data_transmitted = false;
	data_received = false;
	rec_bytes = 0;
	memset(global_rx_buffer, 0, sizeof(global_rx_buffer));

	k_event_init(&uart_events);

	ret = uart_configure(tx_dev, &uart_cfg_tx);
	if (ret != 0) {
		TC_PRINT("TX uart_configure failed (ret=%d)\n", ret);
		return -1;
	}
	ret = uart_configure(rx_dev, &uart_cfg_rx);
	if (ret != 0) {
		TC_PRINT("RX uart_configure failed (ret=%d)\n", ret);
		return -1;
	}

	TC_PRINT("[ STARTED ] External loopback %s at baudrate %d\n",
		 str, uart_cfg_tx.baudrate);

	int ret_rx = uart_irq_callback_user_data_set(rx_dev,
						     uart_external_loopback_rx_cb,
						     &rx_ctx);
	if (uart_irq_cb(ret_rx) == -1) {
		TC_PRINT("[ FAILED ] RX callback set failed for %s\n", str);
		return -1;
	}
	uart_irq_rx_enable(rx_dev);

	int ret_tx = uart_irq_callback_user_data_set(tx_dev,
						     uart_external_loopback_tx_cb,
						     &tx_ctx);
	if (uart_irq_cb(ret_tx) == -1) {
		TC_PRINT("[ FAILED ] TX callback set failed for %s\n", str);
		uart_irq_rx_disable(rx_dev);
		return -1;
	}
	uart_irq_tx_enable(tx_dev);

	int64_t deadline = k_uptime_get() +
			    uart_test_timeout_ms(uart_cfg_tx.baudrate, size);

	while (!data_transmitted || !data_received) {
		(void)k_event_wait(&uart_events, TX_DONE_EVENT | RX_DONE_EVENT,
				   false, K_MSEC(50));

		if (k_uptime_get() > deadline) {
			TC_PRINT("TIMEOUT: %s (sent=%d/%d, recv=%d/%d)\n",
				 str, char_sent, size, rec_bytes, size);
			break;
		}
	}

	uart_irq_tx_disable(tx_dev);
	uart_irq_rx_disable(rx_dev);

	if (data_transmitted && data_received &&
	    char_sent == size && rec_bytes == size &&
	    memcmp(tx_buf, global_rx_buffer, size) == 0) {
		TC_PRINT("[ PASSED ] %s at baudrate %d (sent=%d, recv=%d)\n",
			 str, uart_cfg_tx.baudrate, char_sent, rec_bytes);
		return 0;
	}

	TC_PRINT("[ FAILED ] %s (sent=%d/%d, recv=%d/%d)\n",
		 str, char_sent, size, rec_bytes, size);
	return -1;
}

/*
 * Helper: reset uart_cfg_tx and uart_cfg_rx to default 8N1/no-flow
 * at the given baud rate.
 */
static void ext_lb_set_config(uint32_t baudrate)
{
	uart_cfg_tx.baudrate  = baudrate;
	uart_cfg_tx.parity    = UART_CFG_PARITY_NONE;
	uart_cfg_tx.stop_bits = UART_CFG_STOP_BITS_1;
	uart_cfg_tx.data_bits = UART_CFG_DATA_BITS_8;
	uart_cfg_tx.flow_ctrl = UART_CFG_FLOW_CTRL_NONE;

	uart_cfg_rx.baudrate  = baudrate;
	uart_cfg_rx.parity    = UART_CFG_PARITY_NONE;
	uart_cfg_rx.stop_bits = UART_CFG_STOP_BITS_1;
	uart_cfg_rx.data_bits = UART_CFG_DATA_BITS_8;
	uart_cfg_rx.flow_ctrl = UART_CFG_FLOW_CTRL_NONE;
}

/**
 * @brief Test external loopback with interrupt for transmitting strings.
 *
 * Generates a 32-byte string and transmits it via UART using interrupt
 * mode, then verifies the received data matches the transmitted data.
 */
ZTEST(uart_external_loopback, test_interrupt_external_loopback_string)
{
	unsigned char tx_string[33];

	for (int i = 0; i < 32; i++) {
		tx_string[i] = (unsigned char)('A' + (i % 26));
	}
	tx_string[32] = '\0';

	ext_lb_set_config(get_uart_baudrate_from_dt());

	int size = strlen((const char *)tx_string);
	int ret = test_external_loopback_interrupt(tx_string, size, "String-32B");

	print_buffer_hex_ascii("Sent", tx_string, size);
	print_buffer_hex_ascii("Received", global_rx_buffer, rec_bytes);
	zassert_equal(ret, 0, "External loopback string test failed");
}

/**
 * @brief Test external loopback with interrupt for transmitting numbers.
 *
 * Transmits numeric string data via UART using interrupt mode and
 * verifies the received data matches the transmitted data.
 */
ZTEST(uart_external_loopback, test_interrupt_external_loopback_numbers)
{
	unsigned char tx_num[] = "44332232232";
	int size = strlen((const char *)tx_num);

	ext_lb_set_config(get_uart_baudrate_from_dt());

	int ret = test_external_loopback_interrupt(tx_num, size, "Numbers");

	print_buffer_hex_ascii("Sent", tx_num, size);
	print_buffer_hex_ascii("Received", global_rx_buffer, rec_bytes);
	zassert_equal(ret, 0, "External loopback numbers test failed");
}

/**
 * @brief Test external loopback with interrupt for transmitting binary data (32 bytes).
 *
 * Generates 32 bytes of sequential binary data and transmits it via UART
 * using interrupt mode, then verifies the received data matches.
 */
ZTEST(uart_external_loopback, test_interrupt_external_loopback_binary_data)
{
	uint8_t tx_binary[FIFO_DEPTH];

	for (int i = 0; i < FIFO_DEPTH; i++) {
		tx_binary[i] = (uint8_t)i;
	}

	ext_lb_set_config(get_uart_baudrate_from_dt());

	int size = FIFO_DEPTH;
	int ret = test_external_loopback_interrupt(tx_binary, size, "Binary-32B");

	print_buffer_hex_only("Sent", tx_binary, size);
	print_buffer_hex_only("Received", global_rx_buffer, rec_bytes);
	zassert_equal(ret, 0, "External loopback binary test failed");
}

/**
 * @brief Test external loopback with interrupt for transmitting ASCII data.
 *
 * Transmits 32 bytes of ASCII characters via UART using interrupt mode
 * and verifies the received data matches the transmitted data.
 */
ZTEST(uart_external_loopback, test_interrupt_external_loopback_ascii_data)
{
	char tx_ascii[] = "ABCDEFGHIJKLMNOPQRSTUVWXYZ012345";
	int len = strlen(tx_ascii);

	ext_lb_set_config(get_uart_baudrate_from_dt());

	int ret = test_external_loopback_interrupt((unsigned char *)tx_ascii,
						 len, "ASCII-32B");

	print_buffer_hex_ascii("Sent", (unsigned char *)tx_ascii, len);
	print_buffer_hex_ascii("Received", global_rx_buffer, rec_bytes);
	zassert_equal(ret, 0, "External loopback ASCII test failed");
}

/**
 * @brief Test external loopback with interrupt for transmitting hex data.
 *
 * Transmits 32 bytes of hexadecimal values via UART using interrupt mode
 * and verifies the received data matches the transmitted data.
 */
ZTEST(uart_external_loopback, test_interrupt_external_loopback_hex_data)
{
	unsigned char tx_hex[FIFO_DEPTH] = {
		0x00, 0x11, 0x22, 0x33, 0x44, 0x55, 0x66, 0x77,
		0x88, 0x99, 0xAA, 0xBB, 0xCC, 0xDD, 0xEE, 0xFF,
		0x10, 0x21, 0x32, 0x43, 0x54, 0x65, 0x76, 0x87,
		0x98, 0xA9, 0xBA, 0xCB, 0xDC, 0xED, 0xFE, 0x0F
	};
	int size = sizeof(tx_hex);

	ext_lb_set_config(get_uart_baudrate_from_dt());

	int ret = test_external_loopback_interrupt(tx_hex, size, "HEX-32B");

	print_buffer_hex_only("HEX Sent", tx_hex, size);
	print_buffer_hex_only("HEX Received", global_rx_buffer, rec_bytes);
	zassert_equal(ret, 0, "External loopback HEX test failed");
}

/**
 * @brief Test external loopback across multiple baud rates.
 *
 * Iterates through standard baud rates (9600, 19200, 38400, 57600,
 * 115200, 921600) and verifies successful transmission at each rate.
 */
ZTEST(uart_external_loopback, test_interrupt_external_loopback_multi_baud)
{
	static const uint32_t bauds[] = {
		9600, 19200, 38400, 57600, 115200, 921600
	};
	unsigned char tx_buf[] = "BaudSweep!";
	int size = strlen((const char *)tx_buf);
	int count = 0;

	for (int i = 0; i < ARRAY_SIZE(bauds); i++) {
		ext_lb_set_config(bauds[i]);

		int ret = test_external_loopback_interrupt(tx_buf, size,
							  "MultiBaud");
		if (ret != 0) {
			count++;
			TC_PRINT("External loopback FAILED at baud %d\n",
				 bauds[i]);
		}
	}

	zassert_equal(count, 0,
		      "External loopback multi-baud sweep had failures");
}

/**
 * @brief Test external loopback with different stop bit configurations.
 *
 * Tests all supported stop bit settings (0.5, 1, 1.5, 2) and verifies
 * successful transmission with each configuration.
 */
ZTEST(uart_external_loopback, test_interrupt_external_loopback_stop_bits)
{
	unsigned char tx_buf[] = "StopBitTest!";
	int size = strlen((const char *)tx_buf);
	int tested = 0;
	int failed = 0;

	const struct device *tx_dev = DEVICE_DT_GET(DT_CHOSEN(zephyr_devnode1));
	const struct device *rx_dev = DEVICE_DT_GET(DT_CHOSEN(zephyr_devnode2));

	for (int i = UART_CFG_STOP_BITS_0_5; i <= UART_CFG_STOP_BITS_2; i++) {
		ext_lb_set_config(get_uart_baudrate_from_dt());
		uart_cfg_tx.stop_bits = i;
		uart_cfg_rx.stop_bits = i;

		/* Probe uart_configure to check if this config is supported */
		int cfg_ret = uart_configure(tx_dev, &uart_cfg_tx);

		if (cfg_ret != 0) {
			TC_PRINT("External loopback stop_bits %d -> SKIPPED "
				 "(unsupported, ret=%d)\n", i, cfg_ret);
			continue;
		}
		cfg_ret = uart_configure(rx_dev, &uart_cfg_rx);
		if (cfg_ret != 0) {
			TC_PRINT("External loopback stop_bits %d -> SKIPPED "
				 "(RX unsupported, ret=%d)\n", i, cfg_ret);
			continue;
		}

		int ret = test_external_loopback_interrupt(tx_buf, size,
							  "StopBits");
		if (ret != 0) {
			failed++;
			TC_PRINT("External loopback stop_bits %d -> FAILED\n",
				 i);
		} else {
			tested++;
			TC_PRINT("External loopback stop_bits %d -> PASSED\n",
				 i);
		}
	}

	TC_PRINT("Stop-bits: %d passed, %d failed\n", tested, failed);
	zassert_equal(failed, 0, "Stop bits test failed for %d configuration(s)", failed);
	zassert_true(tested > 0, "No stop-bit configurations were tested successfully");
}

/**
 * @brief Test external loopback with different parity configurations.
 *
 * Tests all supported parity settings (none, odd, even, mark, space)
 * and verifies successful transmission with each configuration.
 */
ZTEST(uart_external_loopback, test_interrupt_external_loopback_parity)
{
	unsigned char tx_buf[] = "ParityTest!";
	int size = strlen((const char *)tx_buf);
	int tested = 0;
	int failed = 0;

	const struct device *tx_dev = DEVICE_DT_GET(DT_CHOSEN(zephyr_devnode1));
	const struct device *rx_dev = DEVICE_DT_GET(DT_CHOSEN(zephyr_devnode2));

	for (int i = UART_CFG_PARITY_NONE; i <= UART_CFG_PARITY_SPACE; i++) {
		ext_lb_set_config(get_uart_baudrate_from_dt());
		uart_cfg_tx.parity = i;
		uart_cfg_rx.parity = i;

		/* Probe uart_configure to check if this config is supported */
		int cfg_ret = uart_configure(tx_dev, &uart_cfg_tx);

		if (cfg_ret != 0) {
			TC_PRINT("External loopback parity %d -> SKIPPED "
				 "(unsupported, ret=%d)\n", i, cfg_ret);
			continue;
		}
		cfg_ret = uart_configure(rx_dev, &uart_cfg_rx);
		if (cfg_ret != 0) {
			TC_PRINT("External loopback parity %d -> SKIPPED "
				 "(RX unsupported, ret=%d)\n", i, cfg_ret);
			continue;
		}

		int ret = test_external_loopback_interrupt(tx_buf, size,
							  "Parity");
		if (ret != 0) {
			failed++;
			TC_PRINT("External loopback parity %d -> FAILED\n", i);
		} else {
			tested++;
			TC_PRINT("External loopback parity %d -> PASSED\n", i);
		}
	}

	TC_PRINT("Parity: %d passed, %d failed\n", tested, failed);
	zassert_equal(failed, 0, "Parity test failed for %d configuration(s)", failed);
	zassert_true(tested > 0, "No parity configurations were tested successfully");
}

/**
 * @brief Test back-to-back external loopback transfers.
 *
 * Performs two consecutive transfers (31 bytes and 32 bytes) to verify
 * the UART can handle multiple transfers without issues.
 */
ZTEST(uart_external_loopback, test_interrupt_external_loopback_back_to_back)
{
	unsigned char tx_a[] = "BackToBack_Test_1_Below_FIFO_XX";
	unsigned char tx_b[] = "BackToBack_Test_2_Exact_FIFO_XX!";
	int size_a = 31;
	int size_b = 32;


	ext_lb_set_config(get_uart_baudrate_from_dt());
	int ret = test_external_loopback_interrupt(tx_a, size_a, "BackToBack-31B");

	zassert_equal(ret, 0, "Back-to-back transfer 1 (31B) failed");

	ext_lb_set_config(get_uart_baudrate_from_dt());
	ret = test_external_loopback_interrupt(tx_b, size_b, "BackToBack-32B");
	zassert_equal(ret, 0, "Back-to-back transfer 2 (32B) failed");
}
```
